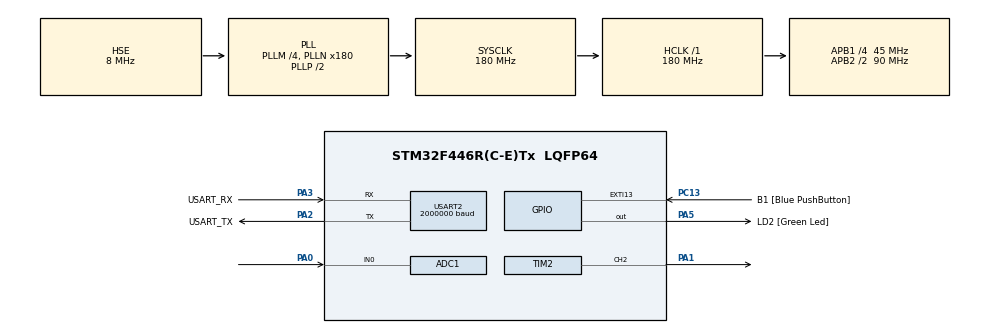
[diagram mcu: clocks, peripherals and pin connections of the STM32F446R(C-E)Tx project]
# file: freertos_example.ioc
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ADC1.Channel-0\#ChannelRegularConversion=ADC_CHANNEL_0
ADC1.ClockPrescaler=ADC_CLOCK_SYNC_PCLK_DIV8
ADC1.ContinuousConvMode=ENABLE
ADC1.NbrOfConversionFlag=1
ADC1.Rank-0\#ChannelRegularConversion=1
ADC1.SamplingTime-0\#ChannelRegularConversion=ADC_SAMPLETIME_3CYCLES
ADC1.master=1
Dma.Request0=USART2_RX
Dma.Request1=USART2_TX
Dma.USART2_RX.0.Direction=DMA_PERIPH_TO_MEMORY
Dma.USART2_RX.0.FIFOMode=DMA_FIFOMODE_DISABLE
Dma.USART2_RX.0.Instance=DMA1_Stream5
Dma.USART2_RX.0.MemDataAlignment=DMA_MDATAALIGN_BYTE
Dma.USART2_RX.0.MemInc=DMA_MINC_ENABLE
Dma.USART2_RX.0.Mode=DMA_NORMAL
Dma.USART2_RX.0.PeriphDataAlignment=DMA_PDATAALIGN_BYTE
Dma.USART2_RX.0.PeriphInc=DMA_PINC_DISABLE
Dma.USART2_RX.0.Priority=DMA_PRIORITY_LOW
Dma.USART2_TX.1.Direction=DMA_MEMORY_TO_PERIPH
Dma.USART2_TX.1.FIFOMode=DMA_FIFOMODE_DISABLE
Dma.USART2_TX.1.Instance=DMA1_Stream6
Dma.USART2_TX.1.MemDataAlignment=DMA_MDATAALIGN_BYTE
Dma.USART2_TX.1.MemInc=DMA_MINC_ENABLE
Dma.USART2_TX.1.Mode=DMA_NORMAL
Dma.USART2_TX.1.PeriphDataAlignment=DMA_PDATAALIGN_BYTE
Dma.USART2_TX.1.PeriphInc=DMA_PINC_DISABLE
Dma.USART2_TX.1.Priority=DMA_PRIORITY_LOW
FREERTOS.Tasks01=defaultTask,0,128,StartDefaultTask,Default,NULL,Dynamic,NULL,NULL
Mcu.Family=STM32F4
Mcu.Name=STM32F446R(C-E)Tx
Mcu.Package=LQFP64
NVIC.DMA1_Stream5_IRQn=true\:5\:0\:false\:false\:true\:true\:false\:true\:true
NVIC.DMA1_Stream6_IRQn=true\:5\:0\:false\:false\:true\:true\:false\:true\:true
NVIC.PriorityGroup=NVIC_PRIORITYGROUP_4
NVIC.TIM7_IRQn=true\:15\:0\:false\:false\:true\:false\:false\:true\:true
NVIC.TimeBase=TIM7_IRQn
NVIC.TimeBaseIP=TIM7
NVIC.USART2_IRQn=true\:5\:0\:false\:false\:true\:true\:true\:true\:true
PA0-WKUP.Signal=ADCx_IN0
PA1.Signal=S_TIM2_CH2
PA13.GPIO_Label=TMS
PA13.Mode=Serial_Wire
PA13.Signal=SYS_JTMS-SWDIO
PA14.GPIO_Label=TCK
PA14.Mode=Serial_Wire
PA14.Signal=SYS_JTCK-SWCLK
PA2.GPIO_Label=USART_TX
PA2.Mode=Asynchronous
PA2.Signal=USART2_TX
PA3.GPIO_Label=USART_RX
PA3.Mode=Asynchronous
PA3.Signal=USART2_RX
PA5.GPIO_Label=LD2 [Green Led]
PA5.Signal=GPIO_Output
PB3.GPIO_Label=SWO
PB3.Signal=SYS_JTDO-SWO
PC13.GPIO_Label=B1 [Blue PushButton]
PC13.GPIO_ModeDefaultEXTI=GPIO_MODE_IT_FALLING
PC13.Signal=GPXTI13
PC14-OSC32_IN.Signal=RCC_OSC32_IN
PC15-OSC32_OUT.Signal=RCC_OSC32_OUT
PH0-OSC_IN.Mode=HSE-External-Oscillator
PH0-OSC_IN.Signal=RCC_OSC_IN
PH1-OSC_OUT.Mode=HSE-External-Oscillator
PH1-OSC_OUT.Signal=RCC_OSC_OUT
ProjectManager.HeapSize=0x200
ProjectManager.StackSize=0x400
ProjectManager.TargetToolchain=CMake
RCC.AHBFreq_Value=180000000
RCC.APB1CLKDivider=RCC_HCLK_DIV4
RCC.APB1Freq_Value=45000000
RCC.APB1TimFreq_Value=90000000
RCC.APB2CLKDivider=RCC_HCLK_DIV2
RCC.APB2Freq_Value=90000000
RCC.APB2TimFreq_Value=180000000
RCC.CortexFreq_Value=180000000
RCC.FLatency-AdvancedSettings=FLASH_LATENCY_5
RCC.HCLKFreq_Value=180000000
RCC.HSE_VALUE=8000000
RCC.HSI_VALUE=16000000
RCC.LSE_VALUE=32768
RCC.PLLM=4
RCC.PLLN=180
RCC.PLLSourceVirtual=RCC_PLLSOURCE_HSE
RCC.SYSCLKFreq_VALUE=180000000
RCC.SYSCLKSource=RCC_SYSCLKSOURCE_PLLCLK
RCC.USBFreq_Value=180000000
RCC.VCOOutputFreq_Value=360000000
SH.ADCx_IN0.0=ADC1_IN0,IN0
SH.S_TIM2_CH2.0=TIM2_CH2,PWM Generation2 CH2
TIM2.Channel-PWM\ Generation2\ CH2=TIM_CHANNEL_2
TIM2.Period=100-1
TIM2.Prescaler=90-1
TIM2.Pulse-PWM\ Generation2\ CH2=50
USART2.BaudRate=2000000
USART2.VirtualMode=VM_ASYNC
VP_FREERTOS_VS_CMSIS_V1.Mode=CMSIS_V1
VP_SYS_VS_tim7.Mode=TIM7
board=NUCLEO-F446RE

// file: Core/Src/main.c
/* USER CODE BEGIN Header */
/**
  ******************************************************************************
  * @file           : main.c
  * @brief          : Main program body
  ******************************************************************************
  * @attention
  *
  * Copyright (c) 2025 STMicroelectronics.
  * All rights reserved.
  *
  * This software is licensed under terms that can be found in the LICENSE file
  * in the root directory of this software component.
  * If no LICENSE file comes with this software, it is provided AS-IS.
  *
  ******************************************************************************
  */
/* USER CODE END Header */
#include "main.h"
#include "cmsis_os.h"

/* USER CODE BEGIN Includes */
#include "FreeRTOS.h"
#include "uart_driver_config.h"
#include "uart_driver.h"
#include "logging.h"
#include "fault_module.h"

/* USER CODE END Includes */

ADC_HandleTypeDef hadc1;

TIM_HandleTypeDef htim2;

UART_HandleTypeDef huart2;
DMA_HandleTypeDef hdma_usart2_rx;
DMA_HandleTypeDef hdma_usart2_tx;

osThreadId defaultTaskHandle;
/* USER CODE BEGIN PV */
uart_drv_t shared_uart;

/* USER CODE END PV */

void SystemClock_Config(void);
static void MX_GPIO_Init(void);
static void MX_DMA_Init(void);
static void MX_USART2_UART_Init(void);
static void MX_ADC1_Init(void);
static void MX_TIM2_Init(void);
void StartDefaultTask(void const * argument);

int main(void)
{

  /* MCU Configuration--------------------------------------------------------*/

  /* Reset of all peripherals, Initializes the Flash interface and the Systick. */
  HAL_Init();

  /* Configure the system clock */
  SystemClock_Config();

  /* Initialize all configured peripherals */
  MX_GPIO_Init();
  MX_DMA_Init();
  MX_USART2_UART_Init();
  MX_ADC1_Init();
  MX_TIM2_Init();
  /* USER CODE BEGIN 2 */
  uart_system_init(&shared_uart, &huart2, &hdma_usart2_tx, &hdma_usart2_rx);

  /* USER CODE END 2 */

  /* Create the thread(s) */
  /* definition and creation of defaultTask */
  osThreadDef(defaultTask, StartDefaultTask, osPriorityNormal, 0, 128);
  defaultTaskHandle = osThreadCreate(osThread(defaultTask), NULL);

  /* Start scheduler */
  osKernelStart();

  /* We should never get here as control is now taken by the scheduler */

  /* Infinite loop */
  while (1)
  {

  }
}

void SystemClock_Config(void)
{
  RCC_OscInitTypeDef RCC_OscInitStruct = {0};
  RCC_ClkInitTypeDef RCC_ClkInitStruct = {0};

  /** Configure the main internal regulator output voltage
  */
  __HAL_RCC_PWR_CLK_ENABLE();
  __HAL_PWR_VOLTAGESCALING_CONFIG(PWR_REGULATOR_VOLTAGE_SCALE1);

  /** Initializes the RCC Oscillators according to the specified parameters
  * in the RCC_OscInitTypeDef structure.
  */
  RCC_OscInitStruct.OscillatorType = RCC_OSCILLATORTYPE_HSE;
  RCC_OscInitStruct.HSEState = RCC_HSE_ON;
  RCC_OscInitStruct.PLL.PLLState = RCC_PLL_ON;
  RCC_OscInitStruct.PLL.PLLSource = RCC_PLLSOURCE_HSE;
  RCC_OscInitStruct.PLL.PLLM = 4;
  RCC_OscInitStruct.PLL.PLLN = 180;
  RCC_OscInitStruct.PLL.PLLP = RCC_PLLP_DIV2;
  RCC_OscInitStruct.PLL.PLLQ = 2;
  RCC_OscInitStruct.PLL.PLLR = 2;
  if (HAL_RCC_OscConfig(&RCC_OscInitStruct) != HAL_OK)
  {
    Error_Handler();
  }

  /** Activate the Over-Drive mode
  */
  if (HAL_PWREx_EnableOverDrive() != HAL_OK)
  {
    Error_Handler();
  }

  /** Initializes the CPU, AHB and APB buses clocks
  */
  RCC_ClkInitStruct.ClockType = RCC_CLOCKTYPE_HCLK|RCC_CLOCKTYPE_SYSCLK
                              |RCC_CLOCKTYPE_PCLK1|RCC_CLOCKTYPE_PCLK2;
  RCC_ClkInitStruct.SYSCLKSource = RCC_SYSCLKSOURCE_PLLCLK;
  RCC_ClkInitStruct.AHBCLKDivider = RCC_SYSCLK_DIV1;
  RCC_ClkInitStruct.APB1CLKDivider = RCC_HCLK_DIV4;
  RCC_ClkInitStruct.APB2CLKDivider = RCC_HCLK_DIV2;

  if (HAL_RCC_ClockConfig(&RCC_ClkInitStruct, FLASH_LATENCY_5) != HAL_OK)
  {
    Error_Handler();
  }
}

static void MX_ADC1_Init(void)
{

  ADC_ChannelConfTypeDef sConfig = {0};

  /** Configure the global features of the ADC (Clock, Resolution, Data Alignment and number of conversion)
  */
  hadc1.Instance = ADC1;
  hadc1.Init.ClockPrescaler = ADC_CLOCK_SYNC_PCLK_DIV8;
  hadc1.Init.Resolution = ADC_RESOLUTION_12B;
  hadc1.Init.ScanConvMode = DISABLE;
  hadc1.Init.ContinuousConvMode = ENABLE;
  hadc1.Init.DiscontinuousConvMode = DISABLE;
  hadc1.Init.ExternalTrigConvEdge = ADC_EXTERNALTRIGCONVEDGE_NONE;
  hadc1.Init.ExternalTrigConv = ADC_SOFTWARE_START;
  hadc1.Init.DataAlign = ADC_DATAALIGN_RIGHT;
  hadc1.Init.NbrOfConversion = 1;
  hadc1.Init.DMAContinuousRequests = DISABLE;
  hadc1.Init.EOCSelection = ADC_EOC_SINGLE_CONV;
  if (HAL_ADC_Init(&hadc1) != HAL_OK)
  {
    Error_Handler();
  }

  /** Configure for the selected ADC regular channel its corresponding rank in the sequencer and its sample time.
  */
  sConfig.Channel = ADC_CHANNEL_0;
  sConfig.Rank = 1;
  sConfig.SamplingTime = ADC_SAMPLETIME_3CYCLES;
  if (HAL_ADC_ConfigChannel(&hadc1, &sConfig) != HAL_OK)
  {
    Error_Handler();
  }

}

static void MX_TIM2_Init(void)
{

  TIM_MasterConfigTypeDef sMasterConfig = {0};
  TIM_OC_InitTypeDef sConfigOC = {0};

  htim2.Instance = TIM2;
  htim2.Init.Prescaler = 90-1;
  htim2.Init.CounterMode = TIM_COUNTERMODE_UP;
  htim2.Init.Period = 100-1;
  htim2.Init.ClockDivision = TIM_CLOCKDIVISION_DIV1;
  htim2.Init.AutoReloadPreload = TIM_AUTORELOAD_PRELOAD_DISABLE;
  if (HAL_TIM_PWM_Init(&htim2) != HAL_OK)
  {
    Error_Handler();
  }
  sMasterConfig.MasterOutputTrigger = TIM_TRGO_RESET;
  sMasterConfig.MasterSlaveMode = TIM_MASTERSLAVEMODE_DISABLE;
  if (HAL_TIMEx_MasterConfigSynchronization(&htim2, &sMasterConfig) != HAL_OK)
  {
    Error_Handler();
  }
  sConfigOC.OCMode = TIM_OCMODE_PWM1;
  sConfigOC.Pulse = 50;
  sConfigOC.OCPolarity = TIM_OCPOLARITY_HIGH;
  sConfigOC.OCFastMode = TIM_OCFAST_DISABLE;
  if (HAL_TIM_PWM_ConfigChannel(&htim2, &sConfigOC, TIM_CHANNEL_2) != HAL_OK)
  {
    Error_Handler();
  }
  HAL_TIM_MspPostInit(&htim2);

}

static void MX_USART2_UART_Init(void)
{

  huart2.Instance = USART2;
  huart2.Init.BaudRate = 250000;
  huart2.Init.WordLength = UART_WORDLENGTH_8B;
  huart2.Init.StopBits = UART_STOPBITS_1;
  huart2.Init.Parity = UART_PARITY_NONE;
  huart2.Init.Mode = UART_MODE_TX_RX;
  huart2.Init.HwFlowCtl = UART_HWCONTROL_NONE;
  huart2.Init.OverSampling = UART_OVERSAMPLING_16;
  if (HAL_UART_Init(&huart2) != HAL_OK)
  {
    Error_Handler();
  }

}

static void MX_DMA_Init(void)
{

  /* DMA controller clock enable */
  __HAL_RCC_DMA1_CLK_ENABLE();

  /* DMA interrupt init */
  /* DMA1_Stream5_IRQn interrupt configuration */
  HAL_NVIC_SetPriority(DMA1_Stream5_IRQn, 5, 0);
  HAL_NVIC_EnableIRQ(DMA1_Stream5_IRQn);
  /* DMA1_Stream6_IRQn interrupt configuration */
  HAL_NVIC_SetPriority(DMA1_Stream6_IRQn, 5, 0);
  HAL_NVIC_EnableIRQ(DMA1_Stream6_IRQn);

}

static void MX_GPIO_Init(void)
{
  GPIO_InitTypeDef GPIO_InitStruct = {0};

  /* GPIO Ports Clock Enable */
  __HAL_RCC_GPIOC_CLK_ENABLE();
  __HAL_RCC_GPIOH_CLK_ENABLE();
  __HAL_RCC_GPIOA_CLK_ENABLE();
  __HAL_RCC_GPIOB_CLK_ENABLE();

  /*Configure GPIO pin Output Level */
  HAL_GPIO_WritePin(LD2_GPIO_Port, LD2_Pin, GPIO_PIN_RESET);

  /*Configure GPIO pin : B1_Pin */
  GPIO_InitStruct.Pin = B1_Pin;
  GPIO_InitStruct.Mode = GPIO_MODE_IT_FALLING;
  GPIO_InitStruct.Pull = GPIO_NOPULL;
  HAL_GPIO_Init(B1_GPIO_Port, &GPIO_InitStruct);

  /*Configure GPIO pin : LD2_Pin */
  GPIO_InitStruct.Pin = LD2_Pin;
  GPIO_InitStruct.Mode = GPIO_MODE_OUTPUT_PP;
  GPIO_InitStruct.Pull = GPIO_NOPULL;
  GPIO_InitStruct.Speed = GPIO_SPEED_FREQ_LOW;
  HAL_GPIO_Init(LD2_GPIO_Port, &GPIO_InitStruct);

}

void StartDefaultTask(void const * argument)
{
  for(;;)
  {
    osDelay(1);
  }
}

void HAL_TIM_PeriodElapsedCallback(TIM_HandleTypeDef *htim)
{
  if (htim->Instance == TIM7)
  {
    HAL_IncTick();
  }
}

void Error_Handler(void)
{
  __disable_irq();
  while (1)
  {
  }
}
